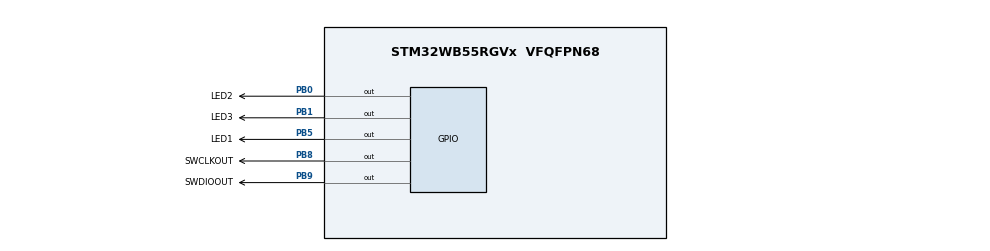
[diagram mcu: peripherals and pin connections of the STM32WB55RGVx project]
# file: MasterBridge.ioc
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Mcu.Family=STM32WB
Mcu.Name=STM32WB55RGVx
Mcu.Package=VFQFPN68
NVIC.PriorityGroup=NVIC_PRIORITYGROUP_4
NVIC.TIM1_UP_TIM16_IRQn=true\:0\:0\:false\:false\:true\:true\:true\:true
PB0.GPIO_Label=LED2
PB0.Signal=GPIO_Output
PB1.GPIO_Label=LED3
PB1.Signal=GPIO_Output
PB5.GPIO_Label=LED1
PB5.Signal=GPIO_Output
PB8.GPIO_Label=SWCLKOUT
PB8.GPIO_Speed=GPIO_SPEED_FREQ_VERY_HIGH
PB8.Signal=GPIO_Output
PB9.GPIO_Label=SWDIOOUT
PB9.GPIO_Speed=GPIO_SPEED_FREQ_VERY_HIGH
PB9.Signal=GPIO_Output
ProjectManager.HeapSize=0x200
ProjectManager.StackSize=0x400
ProjectManager.TargetToolchain=STM32CubeIDE
RCC.ADCFreq_Value=64000000
RCC.AHB2CLKDivider=RCC_SYSCLK_DIV2
RCC.AHBFreq_Value=64000000
RCC.APB1Freq_Value=64000000
RCC.APB1TimFreq_Value=64000000
RCC.APB2Freq_Value=64000000
RCC.APB2TimFreq_Value=64000000
RCC.APB3Freq_Value=16000000
RCC.CortexFreq_Value=64000000
RCC.HCLKFreq_Value=64000000
RCC.HSE_VALUE=8000000
RCC.HSI48_VALUE=48000000
RCC.HSI_VALUE=16000000
RCC.LSE_VALUE=32768
RCC.MSIClockRange=RCC_MSIRANGE_8
RCC.SYSCLKFreq_VALUE=64000000
RCC.SYSCLKSource=RCC_SYSCLKSOURCE_PLLCLK
RCC.USBFreq_Value=64000000
RCC.VCOOutputFreq_Value=128000000
TIM1.Period=7999
TIM1.Prescaler=7999
VP_MEMORYMAP_VS_MEMORYMAP.Mode=CurAppReg
VP_TIM1_VS_ClockSourceINT.Mode=Internal
board=custom

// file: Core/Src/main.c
/* USER CODE BEGIN Header */
/**
  ******************************************************************************
  * @file           : main.c
  * @brief          : Main program body
  ******************************************************************************
  * @attention
  *
  * Copyright (c) 2026 STMicroelectronics.
  * All rights reserved.
  *
  * This software is licensed under terms that can be found in the LICENSE file
  * in the root directory of this software component.
  * If no LICENSE file comes with this software, it is provided AS-IS.
  *
  ******************************************************************************
  */
/* USER CODE END Header */
#include "main.h"

/* USER CODE BEGIN Includes */
#include "swdprotocol.h"
#include "master.h"
/* USER CODE END Includes */

TIM_HandleTypeDef htim1;

void SystemClock_Config(void);
void PeriphCommonClock_Config(void);
static void MX_GPIO_Init(void);
static void MX_TIM1_Init(void);

int main(void)
{

  /* MCU Configuration--------------------------------------------------------*/

  /* Reset of all peripherals, Initializes the Flash interface and the Systick. */
  HAL_Init();

  /* Configure the system clock */
  SystemClock_Config();

  /* Configure the peripherals common clocks */
  PeriphCommonClock_Config();

  /* Initialize all configured peripherals */
  MX_GPIO_Init();
  MX_TIM1_Init();
  /* USER CODE BEGIN 2 */

  // Enable TIM1
  TIM1->DIER |= TIM_DIER_UIE;
  TIM1->CR1 |= TIM_CR1_CEN;

  /* USER CODE END 2 */

  /* Infinite loop */
  while (1){

  }
}

void SystemClock_Config(void)
{
  RCC_OscInitTypeDef RCC_OscInitStruct = {0};
  RCC_ClkInitTypeDef RCC_ClkInitStruct = {0};

  /** Configure the main internal regulator output voltage
  */
  __HAL_PWR_VOLTAGESCALING_CONFIG(PWR_REGULATOR_VOLTAGE_SCALE1);

  /** Initializes the RCC Oscillators according to the specified parameters
  * in the RCC_OscInitTypeDef structure.
  */
  RCC_OscInitStruct.OscillatorType = RCC_OSCILLATORTYPE_HSI|RCC_OSCILLATORTYPE_MSI;
  RCC_OscInitStruct.HSIState = RCC_HSI_ON;
  RCC_OscInitStruct.MSIState = RCC_MSI_ON;
  RCC_OscInitStruct.HSICalibrationValue = RCC_HSICALIBRATION_DEFAULT;
  RCC_OscInitStruct.MSICalibrationValue = RCC_MSICALIBRATION_DEFAULT;
  RCC_OscInitStruct.MSIClockRange = RCC_MSIRANGE_8;
  RCC_OscInitStruct.PLL.PLLState = RCC_PLL_ON;
  RCC_OscInitStruct.PLL.PLLSource = RCC_PLLSOURCE_MSI;
  RCC_OscInitStruct.PLL.PLLM = RCC_PLLM_DIV1;
  RCC_OscInitStruct.PLL.PLLN = 8;
  RCC_OscInitStruct.PLL.PLLP = RCC_PLLP_DIV2;
  RCC_OscInitStruct.PLL.PLLR = RCC_PLLR_DIV2;
  RCC_OscInitStruct.PLL.PLLQ = RCC_PLLQ_DIV2;
  if (HAL_RCC_OscConfig(&RCC_OscInitStruct) != HAL_OK)
  {
    Error_Handler();
  }

  /** Configure the SYSCLKSource, HCLK, PCLK1 and PCLK2 clocks dividers
  */
  RCC_ClkInitStruct.ClockType = RCC_CLOCKTYPE_HCLK4|RCC_CLOCKTYPE_HCLK2
                              |RCC_CLOCKTYPE_HCLK|RCC_CLOCKTYPE_SYSCLK
                              |RCC_CLOCKTYPE_PCLK1|RCC_CLOCKTYPE_PCLK2;
  RCC_ClkInitStruct.SYSCLKSource = RCC_SYSCLKSOURCE_PLLCLK;
  RCC_ClkInitStruct.AHBCLKDivider = RCC_SYSCLK_DIV1;
  RCC_ClkInitStruct.APB1CLKDivider = RCC_HCLK_DIV1;
  RCC_ClkInitStruct.APB2CLKDivider = RCC_HCLK_DIV1;
  RCC_ClkInitStruct.AHBCLK2Divider = RCC_SYSCLK_DIV2;
  RCC_ClkInitStruct.AHBCLK4Divider = RCC_SYSCLK_DIV1;

  if (HAL_RCC_ClockConfig(&RCC_ClkInitStruct, FLASH_LATENCY_3) != HAL_OK)
  {
    Error_Handler();
  }
}

void PeriphCommonClock_Config(void)
{
  RCC_PeriphCLKInitTypeDef PeriphClkInitStruct = {0};

  /** Initializes the peripherals clock
  */
  PeriphClkInitStruct.PeriphClockSelection = RCC_PERIPHCLK_SMPS;
  PeriphClkInitStruct.SmpsClockSelection = RCC_SMPSCLKSOURCE_HSI;
  PeriphClkInitStruct.SmpsDivSelection = RCC_SMPSCLKDIV_RANGE1;

  if (HAL_RCCEx_PeriphCLKConfig(&PeriphClkInitStruct) != HAL_OK)
  {
    Error_Handler();
  }
}

static void MX_TIM1_Init(void)
{

  TIM_ClockConfigTypeDef sClockSourceConfig = {0};
  TIM_MasterConfigTypeDef sMasterConfig = {0};

  htim1.Instance = TIM1;
  htim1.Init.Prescaler = 7999;
  htim1.Init.CounterMode = TIM_COUNTERMODE_UP;
  htim1.Init.Period = 7999;
  htim1.Init.ClockDivision = TIM_CLOCKDIVISION_DIV1;
  htim1.Init.RepetitionCounter = 0;
  htim1.Init.AutoReloadPreload = TIM_AUTORELOAD_PRELOAD_DISABLE;
  if (HAL_TIM_Base_Init(&htim1) != HAL_OK)
  {
    Error_Handler();
  }
  sClockSourceConfig.ClockSource = TIM_CLOCKSOURCE_INTERNAL;
  if (HAL_TIM_ConfigClockSource(&htim1, &sClockSourceConfig) != HAL_OK)
  {
    Error_Handler();
  }
  sMasterConfig.MasterOutputTrigger = TIM_TRGO_RESET;
  sMasterConfig.MasterOutputTrigger2 = TIM_TRGO2_RESET;
  sMasterConfig.MasterSlaveMode = TIM_MASTERSLAVEMODE_DISABLE;
  if (HAL_TIMEx_MasterConfigSynchronization(&htim1, &sMasterConfig) != HAL_OK)
  {
    Error_Handler();
  }

}

static void MX_GPIO_Init(void)
{
  GPIO_InitTypeDef GPIO_InitStruct = {0};

  /* GPIO Ports Clock Enable */
  __HAL_RCC_GPIOB_CLK_ENABLE();

  /*Configure GPIO pin Output Level */
  HAL_GPIO_WritePin(GPIOB, SWCLKOUT_Pin|SWDIOOUT_Pin|LED2_Pin|LED3_Pin
                          |LED1_Pin, GPIO_PIN_RESET);

  /*Configure GPIO pins : SWCLKOUT_Pin SWDIOOUT_Pin */
  GPIO_InitStruct.Pin = SWCLKOUT_Pin|SWDIOOUT_Pin;
  GPIO_InitStruct.Mode = GPIO_MODE_OUTPUT_PP;
  GPIO_InitStruct.Pull = GPIO_NOPULL;
  GPIO_InitStruct.Speed = GPIO_SPEED_FREQ_VERY_HIGH;
  HAL_GPIO_Init(GPIOB, &GPIO_InitStruct);

  /*Configure GPIO pins : LED2_Pin LED3_Pin LED1_Pin */
  GPIO_InitStruct.Pin = LED2_Pin|LED3_Pin|LED1_Pin;
  GPIO_InitStruct.Mode = GPIO_MODE_OUTPUT_PP;
  GPIO_InitStruct.Pull = GPIO_NOPULL;
  GPIO_InitStruct.Speed = GPIO_SPEED_FREQ_LOW;
  HAL_GPIO_Init(GPIOB, &GPIO_InitStruct);

}

void Error_Handler(void)
{
  __disable_irq();
  while (1)
  {
  }
}
